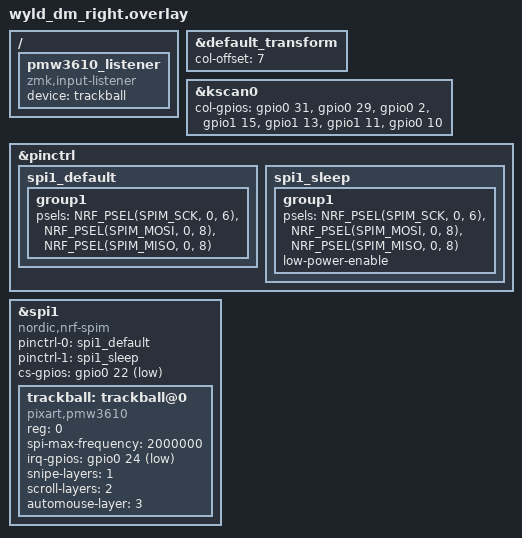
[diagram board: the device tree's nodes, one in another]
// wyld_dm_right.overlay

#include "wyld_dm.dtsi"

&default_transform {
    col-offset = <7>;
};


&kscan0 {
    col-gpios
			= <&gpio0 31  GPIO_ACTIVE_HIGH>  // 0.31
			, <&gpio0 29  GPIO_ACTIVE_HIGH>  // 0.29
            , <&gpio0 2  GPIO_ACTIVE_HIGH>  // 0.02
			, <&gpio1 15  GPIO_ACTIVE_HIGH>  //  1.15
			, <&gpio1 13  GPIO_ACTIVE_HIGH>  // 1.13
			, <&gpio1 11 (GPIO_ACTIVE_HIGH )>  // 1.11
			, <&gpio0 10 (GPIO_ACTIVE_HIGH )>  // 1.10
			;
};

//&right_encoder {
//	status = "okay";
//};

&pinctrl {
    spi1_default: spi1_default {
        group1 {
            psels = <NRF_PSEL(SPIM_SCK, 0, 6)>,
                <NRF_PSEL(SPIM_MOSI, 0, 8)>,
                <NRF_PSEL(SPIM_MISO, 0, 8)>;
        };
    };
    spi1_sleep: spi1_sleep {
        group1 {
            psels = <NRF_PSEL(SPIM_SCK, 0, 6)>,
                <NRF_PSEL(SPIM_MOSI, 0, 8)>,
                <NRF_PSEL(SPIM_MISO, 0, 8)>;
            low-power-enable;
        };
    };
};

&spi1 {
  compatible = "nordic,nrf-spim";
  status = "okay";

  pinctrl-0 = <&spi1_default>;
  pinctrl-1 = <&spi1_sleep>;
  pinctrl-names = "default", "sleep";
  cs-gpios = <&gpio0 22 GPIO_ACTIVE_LOW>;
  trackball: trackball@0 {
      status = "okay";
      compatible = "pixart,pmw3610";
      reg = <0>;
      spi-max-frequency = <2000000>;
      irq-gpios = <&gpio0 24 (GPIO_ACTIVE_LOW | GPIO_PULL_UP)>;
      snipe-layers = <1>;
      scroll-layers = <2>;
      automouse-layer = <3>;
  };
};


/ {
  pmw3610_listener {
    compatible = "zmk,input-listener";
    device = <&trackball>;
  };
};

///{
//	/* auto toggle mouse key layer */
//	trackball_peripheral_auto_mouse_listener {
//		compatible = "zmk,input-behavior-listener";
//		device = <&pd1>;
//		layers = <0>;
//		rotate-deg = <315>;
//		evt-type = <INPUT_EV_REL>;
//		x-input-code = <INPUT_REL_X>;
//		y-input-code = <INPUT_REL_WHEEL>;
//		scale-multiplier = <1>;
//		scale-divisor = <1>;
//		bindings = <&ib_tog_layer 3>;
//	};
//
//	/* input config for mouse scroll mode on momentary mouse scoll layer */
//	trackball_peripheral_scroll_listener {
//		compatible = "zmk,input-behavior-listener";
//		device = <&pd1>;
//		layers = <2>;
//		evt-type = <INPUT_EV_REL>;
//		/* slienting x-axis with alt event code */
//		x-input-code = <INPUT_REL_HWHEEL>;
//		y-input-code = <INPUT_REL_WHEEL>;
//		/* invent scrolling direction */
//		y-invert;
//		/* align to CCW 45 degree */
//		rotate-deg = <180>;
//		/* NOTE 1: This settings do not compitable with y-invert and x-invert */
//		/* NOTE 2: Floating point computation requires alot of ram. */
//		/*         This feature will cuase stackove flow with CONFIG_ZMK_USB_LOGGING=y *
//		/* bind a behavior to down scaling input value to (1/8) */
//		/* NOTE: This behavior is different to scale-divisor. */
//		/*       The delta value is accumlated until result >= 1 after cast. */
//		/*       The scrolling is preented in hi-res and allow precise scrolling */
//		bindings = <&ib_wheel_scaler_x 1 8 &ib_wheel_scaler_y 1 10>;
//	};
//
//	trackball_peripheral_snipe_listener {
//		compatible = "zmk,input-behavior-listener";
//		device = <&pd1>;
//		layers = <3>;
//		evt-type = <INPUT_EV_REL>;
//		x-input-code = <INPUT_REL_X>;
//		y-input-code = <INPUT_REL_Y>;
//		scale-multiplier = <1>;
//		scale-divisor = <1>;
//		/*rotate-deg = <315>;*/
//		bindings = <&ib_snipe_scaler_x 1 8 &ib_snipe_scaler_y 1 8>;
//	};
//
//	/* adjust cooldown waiting period for mouse key layer (MSK) after activated */
//	ib_tog_layer: ib_tog_layer {
//		compatible = "zmk,input-behavior-tog-layer";
//		#binding-cells = <1>;
//		time-to-live-ms = <2000>;
//	};
//
//	/* define a resolution down scaler only for INPUT_REL_WHEEL */
//	ib_wheel_scaler_x: ib_wheel_scaler_x {
//		compatible = "zmk,input-behavior-scaler";
//		#binding-cells = <2>;
//		evt-type = <INPUT_EV_REL>;
//		input-code = <INPUT_REL_WHEEL>;
//	};
//
//	ib_wheel_scaler_y: ib_wheel_scaler_y {
//		compatible = "zmk,input-behavior-scaler";
//		#binding-cells = <2>;
//		evt-type = <INPUT_EV_REL>;
//		input-code = <INPUT_REL_HWHEEL>;
//	};
//
//	ib_snipe_scaler_x: ib_snipe_scaler_x {
//		compatible = "zmk,input-behavior-scaler";
//		#binding-cells = <2>;
//		evt-type = <INPUT_EV_REL>;
//		input-code = <INPUT_REL_X>;
//	};
//
//	ib_snipe_scaler_y: ib_snipe_scaler_y {
//		compatible = "zmk,input-behavior-scaler";
//		#binding-cells = <2>;
//		evt-type = <INPUT_EV_REL>;
//		input-code = <INPUT_REL_Y>;
//	};
//};
